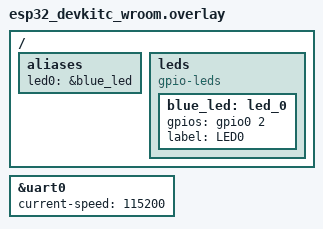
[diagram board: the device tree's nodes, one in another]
/*
 * ESP32 DevKitC WROOM overlay
 * LED0  → GPIO2 (onboard blue LED)
 * UART  → UART0 GPIO1(TX)/GPIO3(RX) → /dev/ttyUSB0
 */
/ {
    aliases {
        led0 = &blue_led;
    };

    leds {
        compatible = "gpio-leds";
        blue_led: led_0 {
            gpios = <&gpio0 2 GPIO_ACTIVE_HIGH>;
            label = "LED0";
        };
    };
};

&uart0 {
    current-speed = <115200>;
    status = "okay";
};
